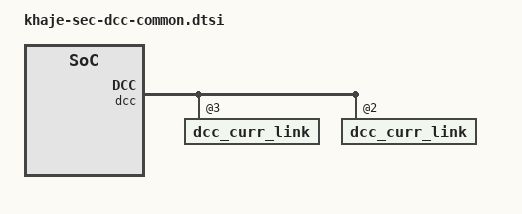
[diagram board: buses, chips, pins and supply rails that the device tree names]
// SPDX-License-Identifier: GPL-2.0
/*
 * COPYRIGHT(C) 2023 Samsung Electronics Co., Ltd. All Right Reserved.
 */

#include <dt-bindings/soc/qcom,dcc_v2.h>


/* config_bengal_dcc_bimc() */
#define config_bengal_dcc_bimc	\
	\
		/* BIMC_M_APP_MPORT */	\
		<DCC_READ 0x4488100 1 0>,	\
		<DCC_READ 0x4488400 2 0>,	\
		<DCC_READ 0x4488410 1 0>,	\
		<DCC_READ 0x4488420 2 0>,	\
		<DCC_READ 0x4488430 2 0>,	\
	\
		/* BIMC_M_GPU_MPORT */	\
		<DCC_READ 0x448c100 1 0>,	\
		<DCC_READ 0x448c400 2 0>,	\
		<DCC_READ 0x448c410 1 0>,	\
		<DCC_READ 0x448c420 2 0>,	\
		<DCC_READ 0x448c430 2 0>,	\
	\
		/* BIMC_M_MMSS_RT_MPORT */	\
		<DCC_READ 0x4490100 1 0>,	\
		<DCC_READ 0x4490400 2 0>,	\
		<DCC_READ 0x4490410 1 0>,	\
		<DCC_READ 0x4490420 2 0>,	\
		<DCC_READ 0x4490430 2 0>,	\
	\
		/* BIMC_M_MMSS_NRT_MPORT */	\
		<DCC_READ 0x4494100 1 0>,	\
		<DCC_READ 0x4494400 2 0>,	\
		<DCC_READ 0x4494410 1 0>,	\
		<DCC_READ 0x4494420 2 0>,	\
		<DCC_READ 0x4494430 2 0>,	\
	\
		/* BIMC_M_TCU_MPORT */	\
		<DCC_READ 0x449810c 1 0>,	\
		<DCC_READ 0x4498400 2 0>,	\
		<DCC_READ 0x4498410 1 0>,	\
		<DCC_READ 0x4498420 2 0>,	\
		<DCC_READ 0x4498430 2 0>,	\
	\
		/* BIMC_M_MDSP_MPORT */	\
		/* <DCC_READ 0x449c100 1 0>, */	\
		/* <DCC_READ 0x449c400 2 0>, */	\
		/* <DCC_READ 0x449c410 1 0>, */	\
		/* <DCC_READ 0x449c420 2 0>, */	\
		/* <DCC_READ 0x449c430 2 0>, */	\
	\
		/* BIMC_M_SYS_MPORT */	\
		<DCC_READ 0x44a0100 1 0>,	\
		<DCC_READ 0x44a0400 2 0>,	\
		<DCC_READ 0x44a0410 1 0>,	\
		<DCC_READ 0x44a0420 2 0>,	\
		<DCC_READ 0x44a0430 2 0>,	\
	\
		/* BIMC_S_DDR0 */	\
		<DCC_READ 0x44b0560 1 0>,	\
		<DCC_READ 0x44b05a0 1 0>,	\
		<DCC_READ 0x44b1800 1 0>,	\
		<DCC_READ 0x44b408c 1 0>,	\
		<DCC_READ 0x44b409c 1 0>,	\
		<DCC_READ 0x44b0520 1 0>,	\
		<DCC_READ 0x44b5070 2 0>,	\
	\
		/*  BIMC_S_SYS_SWAY */	\
		<DCC_READ 0x44bc220 1 0>,	\
		<DCC_READ 0x44bc400 7 0>,	\
		<DCC_READ 0x44bc420 9 0>,	\
		<DCC_READ 0x44bd800 1 0>,	\
		<DCC_READ 0x44c5800 1 0>,	\
		<DCC_READ 0x4480040 2 0>,	\
		<DCC_READ 0x4480810 2 0>,	\
		<DCC_READ 0x44b0a40 1 0>,	\
	\
		/* CH0_DDRCC */	\
		<DCC_READ 0x4506044 1 0>,	\
		<DCC_READ 0x45061dc 1 0>,	\
		<DCC_READ 0x45061ec 1 0>,	\
		<DCC_READ 0x4506028 2 0>,	\
		<DCC_READ 0x4506094 1 0>,	\
		<DCC_READ 0x4506608 1 0>,	\
	\
		/* CCC_MCCC_CH0 */	\
		<DCC_READ 0x447d02c 4 0>,	\
		<DCC_READ 0x447d040 1 0>,	\
	\
		/* CH0_CA0_DDRPHY */	\
		<DCC_READ 0x450002c 2 0>,	\
		<DCC_READ 0x4500094 1 0>,	\
		<DCC_READ 0x450009c 1 0>,	\
		<DCC_READ 0x45000c4 2 0>,	\
		<DCC_READ 0x45003dc 1 0>,	\
		<DCC_READ 0x45005d8 1 0>,	\
	\
		/* CH0_CA1_DDRPHY */	\
		<DCC_READ 0x450102c 2 0>,	\
		<DCC_READ 0x4501094 1 0>,	\
		<DCC_READ 0x450109c 1 0>,	\
		<DCC_READ 0x45010c4 2 0>,	\
		<DCC_READ 0x45013dc 1 0>,	\
		<DCC_READ 0x45015d8 1 0>,	\
	\
		/* CH0_DQ0_DDRPHY */	\
		<DCC_READ 0x450202c 2 0>,	\
		<DCC_READ 0x4502094 1 0>,	\
		<DCC_READ 0x450209c 1 0>,	\
		<DCC_READ 0x45020c4 2 0>,	\
		<DCC_READ 0x45023dc 1 0>,	\
		<DCC_READ 0x45025d8 1 0>,	\
	\
		/* CH0_DQ1_DDRPHY */	\
		<DCC_READ 0x450302c 2 0>,	\
		<DCC_READ 0x4503094 1 0>,	\
		<DCC_READ 0x450309c 1 0>,	\
		<DCC_READ 0x45030c4 2 0>,	\
		<DCC_READ 0x45033dc 1 0>,	\
		<DCC_READ 0x45035d8 1 0>,	\
	\
		/* CH0_DQ2_DDRPHY */	\
		<DCC_READ 0x450402c 2 0>,	\
		<DCC_READ 0x4504094 1 0>,	\
		<DCC_READ 0x450409c 1 0>,	\
		<DCC_READ 0x45040c8 2 0>,	\
		<DCC_READ 0x45043dc 1 0>,	\
		<DCC_READ 0x45045d8 1 0>,	\
	\
		/* CH0_DQ3_DDRPHY */	\
		<DCC_READ 0x450502c 2 0>,	\
		<DCC_READ 0x4505094 1 0>,	\
		<DCC_READ 0x450509c 1 0>,	\
		<DCC_READ 0x45050c4 2 0>,	\
		<DCC_READ 0x45053dc 1 0>,	\
		<DCC_READ 0x45055d8 1 0>

/* config_bengal_dcc_osm() */
#define config_bengal_dcc_osm	\
		<DCC_READ 0x0F522C14 1 0>,	\
		<DCC_READ 0x0F522C1C 1 0>,	\
		<DCC_READ 0x0F522C10 1 0>,	\
		<DCC_READ 0x0F524C10 1 0>,	\
		<DCC_READ 0x0F524C14 1 0>,	\
		<DCC_READ 0x0F524C18 1 0>,	\
		<DCC_READ 0x0F524C1C 1 0>,	\
		<DCC_READ 0x0F521920 1 0>,	\
		<DCC_READ 0x0F52102C 1 0>,	\
		<DCC_READ 0x0F521044 1 0>,	\
		<DCC_READ 0x0F521710 1 0>,	\
		<DCC_READ 0x0F52176C 1 0>,	\
		<DCC_READ 0x0F523920 1 0>,	\
		<DCC_READ 0x0F52302C 1 0>,	\
		<DCC_READ 0x0F523044 1 0>,	\
		<DCC_READ 0x0F523710 1 0>,	\
		<DCC_READ 0x0F52376C 1 0>,	\
		<DCC_READ 0x0F116000 1 0>,	\
		<DCC_READ 0x0F116004 1 0>,	\
		<DCC_READ 0x0F11602C 1 0>,	\
		<DCC_READ 0x0F016000 1 0>,	\
		<DCC_READ 0x0F016004 1 0>,	\
		<DCC_READ 0x0F01602C 1 0>,	\
		<DCC_READ 0x0F111250 1 0>,	\
		<DCC_READ 0x0F111254 1 0>,	\
		<DCC_READ 0x0F111258 1 0>,	\
		<DCC_READ 0x0F11125C 1 0>,	\
		<DCC_READ 0x0F111260 1 0>,	\
		<DCC_READ 0x0F188078 1 0>,	\
		<DCC_READ 0x0F188084 1 0>,	\
		<DCC_READ 0x0F198078 1 0>,	\
		<DCC_READ 0x0F198084 1 0>,	\
		<DCC_READ 0x0F1A8078 1 0>,	\
		<DCC_READ 0x0F1A8084 1 0>,	\
		<DCC_READ 0x0F1B8078 1 0>,	\
		<DCC_READ 0x0F1B8084 1 0>,	\
		<DCC_READ 0x0F521818 1 0>,	\
		<DCC_READ 0x0F52181C 1 0>,	\
		<DCC_READ 0x0F521828 1 0>,	\
		<DCC_READ 0x0F523818 1 0>,	\
		<DCC_READ 0x0F52381C 1 0>,	\
		<DCC_READ 0x0F523828 1 0>,	\
		<DCC_READ 0x0F522C18 1 0>,	\
		<DCC_READ 0x0F111310 1 0>,	\
		<DCC_READ 0x0F111314 1 0>,	\
		<DCC_READ 0x0F111318 1 0>,	\
		<DCC_READ 0x0F01125C 1 0>,	\
		<DCC_READ 0x0F011258 1 0>,	\
		<DCC_READ 0x0F011310 1 0>,	\
		<DCC_READ 0x0F011314 1 0>,	\
		<DCC_READ 0x0F011318 1 0>

/* config_bengal_dcc_gpu() */
#define config_bengal_dcc_gpu	\
	\
		/* GCC */	\
		<DCC_READ 0x141102C 1 0>,	\
		<DCC_READ 0x1436004 1 0>,	\
		<DCC_READ 0x1471154 1 0>,	\
		<DCC_READ 0x141050C 1 0>,	\
		<DCC_READ 0x143600C 1 0>,	\
		<DCC_READ 0x1436018 1 0>,	\
		<DCC_READ 0x1480220 1 0>,	\
		<DCC_READ 0x147C000 1 0>,	\
		<DCC_READ 0x147D000 1 0>,	\
		<DCC_READ 0x14800A0 1 0>,	\
		<DCC_READ 0x1480164 1 0>,	\
		<DCC_READ 0x14801E4 1 0>,	\
		<DCC_READ 0x1436048 1 0>,	\
		<DCC_READ 0x1436040 1 0>,	\
	\
		/* GPUCC */	\
		<DCC_READ 0x5991004 1 0>,	\
		<DCC_READ 0x599100c 1 0>,	\
		<DCC_READ 0x5991010 1 0>,	\
		<DCC_READ 0x5991014 1 0>,	\
		<DCC_READ 0x5991054 1 0>,	\
		<DCC_READ 0x5991060 1 0>,	\
		<DCC_READ 0x599106c 1 0>,	\
		<DCC_READ 0x5991070 1 0>,	\
		<DCC_READ 0x5991074 1 0>,	\
		<DCC_READ 0x5991078 1 0>,	\
		<DCC_READ 0x599107c 1 0>,	\
		<DCC_READ 0x599108c 1 0>,	\
		<DCC_READ 0x5991098 1 0>,	\
		<DCC_READ 0x599109c 1 0>,	\
		<DCC_READ 0x5991540 1 0>,	\
		<DCC_READ 0x5995000 1 0>,	\
		<DCC_READ 0x5995004 1 0>,	\
		<DCC_READ 0x599101C 1 0>,	\
		<DCC_READ 0x5991020 1 0>,	\
		<DCC_READ 0x5990000 1 0>,	\
		<DCC_READ 0x5990100 1 0>,	\
		<DCC_READ 0x5991508 1 0>,	\
		<DCC_READ 0x59910A4 1 0>,	\
		<DCC_READ 0x5991578 1 0>,	\
		<DCC_READ 0x5990010 1 0>,	\
		<DCC_READ 0x5990110 1 0>

/* config_bengal_dcc_gcc_mm() */
#define config_bengal_dcc_gcc_mm	\
		<DCC_READ 0x01480140 1 0>,	\
		<DCC_READ 0x01481140 1 0>,	\
		<DCC_READ 0x0148014C 1 0>,	\
		<DCC_READ 0x0148114C 1 0>,	\
		<DCC_READ 0x01477008 1 0>,	\
		<DCC_READ 0x01439014 1 0>,	\
		<DCC_READ 0x0143900C 1 0>,	\
		<DCC_READ 0x01439004 1 0>,	\
		<DCC_READ 0x01439000 1 0>,	\
		<DCC_READ 0x01439008 1 0>,	\
		<DCC_READ 0x01415010 1 0>,	\
		<DCC_READ 0x01416010 1 0>,	\
		<DCC_READ 0x0142A00C 1 0>

/* config_bengal_dcc_gcc() */
#define config_bengal_dcc_gcc	\
		<DCC_READ 0x1400000 1 0>,	\
		<DCC_READ 0x1400004 1 0>,	\
		<DCC_READ 0x1400008 1 0>,	\
		<DCC_READ 0x140000C 1 0>,	\
		<DCC_READ 0x1400010 1 0>,	\
		<DCC_READ 0x1400014 1 0>,	\
		<DCC_READ 0x1400018 1 0>,	\
		<DCC_READ 0x140001C 1 0>,	\
		<DCC_READ 0x1400020 1 0>,	\
		<DCC_READ 0x1400024 1 0>,	\
		<DCC_READ 0x1401000 1 0>,	\
		<DCC_READ 0x1401004 1 0>,	\
		<DCC_READ 0x1401008 1 0>,	\
		<DCC_READ 0x140100C 1 0>,	\
		<DCC_READ 0x1401010 1 0>,	\
		<DCC_READ 0x1401014 1 0>,	\
		<DCC_READ 0x1401018 1 0>,	\
		<DCC_READ 0x140101C 1 0>,	\
		<DCC_READ 0x1401020 1 0>,	\
		<DCC_READ 0x1401024 1 0>,	\
		<DCC_READ 0x1402000 1 0>,	\
		<DCC_READ 0x1402004 1 0>,	\
		<DCC_READ 0x1402008 1 0>,	\
		<DCC_READ 0x140200C 1 0>,	\
		<DCC_READ 0x1402010 1 0>,	\
		<DCC_READ 0x1402014 1 0>,	\
		<DCC_READ 0x1402018 1 0>,	\
		<DCC_READ 0x140201C 1 0>,	\
		<DCC_READ 0x1402020 1 0>,	\
		<DCC_READ 0x1402024 1 0>,	\
		<DCC_READ 0x1403000 1 0>,	\
		<DCC_READ 0x1403004 1 0>,	\
		<DCC_READ 0x1403008 1 0>,	\
		<DCC_READ 0x140300C 1 0>,	\
		<DCC_READ 0x1403010 1 0>,	\
		<DCC_READ 0x1403014 1 0>,	\
		<DCC_READ 0x1403018 1 0>,	\
		<DCC_READ 0x140301C 1 0>,	\
		<DCC_READ 0x1403020 1 0>,	\
		<DCC_READ 0x1403024 1 0>,	\
		<DCC_READ 0x1404000 1 0>,	\
		<DCC_READ 0x1404004 1 0>,	\
		<DCC_READ 0x1404008 1 0>,	\
		<DCC_READ 0x140400C 1 0>,	\
		<DCC_READ 0x1404010 1 0>,	\
		<DCC_READ 0x1404014 1 0>,	\
		<DCC_READ 0x1404018 1 0>,	\
		<DCC_READ 0x140401C 1 0>,	\
		<DCC_READ 0x1404020 1 0>,	\
		<DCC_READ 0x1404024 1 0>,	\
		<DCC_READ 0x1405000 1 0>,	\
		<DCC_READ 0x1405004 1 0>,	\
		<DCC_READ 0x1405008 1 0>,	\
		<DCC_READ 0x140500C 1 0>,	\
		<DCC_READ 0x1405010 1 0>,	\
		<DCC_READ 0x1405014 1 0>,	\
		<DCC_READ 0x1405018 1 0>,	\
		<DCC_READ 0x140501C 1 0>,	\
		<DCC_READ 0x1405020 1 0>,	\
		<DCC_READ 0x1405024 1 0>,	\
		<DCC_READ 0x1406000 1 0>,	\
		<DCC_READ 0x1406004 1 0>,	\
		<DCC_READ 0x1406008 1 0>,	\
		<DCC_READ 0x140600C 1 0>,	\
		<DCC_READ 0x1406010 1 0>,	\
		<DCC_READ 0x1406014 1 0>,	\
		<DCC_READ 0x1406018 1 0>,	\
		<DCC_READ 0x140601C 1 0>,	\
		<DCC_READ 0x1406020 1 0>,	\
		<DCC_READ 0x1406024 1 0>,	\
		<DCC_READ 0x1407000 1 0>,	\
		<DCC_READ 0x1407004 1 0>,	\
		<DCC_READ 0x1407008 1 0>,	\
		<DCC_READ 0x140700C 1 0>,	\
		<DCC_READ 0x1407010 1 0>,	\
		<DCC_READ 0x1407014 1 0>,	\
		<DCC_READ 0x1407018 1 0>,	\
		<DCC_READ 0x140701C 1 0>,	\
		<DCC_READ 0x1407020 1 0>,	\
		<DCC_READ 0x1407024 1 0>,	\
		<DCC_READ 0x1407028 1 0>,	\
		<DCC_READ 0x140702C 1 0>,	\
		<DCC_READ 0x1407030 1 0>,	\
		<DCC_READ 0x1407034 1 0>,	\
		<DCC_READ 0x1408000 1 0>,	\
		<DCC_READ 0x1408004 1 0>,	\
		<DCC_READ 0x1408008 1 0>,	\
		<DCC_READ 0x140800C 1 0>,	\
		<DCC_READ 0x1408010 1 0>,	\
		<DCC_READ 0x1408014 1 0>,	\
		<DCC_READ 0x1408018 1 0>,	\
		<DCC_READ 0x140801C 1 0>,	\
		<DCC_READ 0x1408020 1 0>,	\
		<DCC_READ 0x1408024 1 0>,	\
		<DCC_READ 0x1409000 1 0>,	\
		<DCC_READ 0x1409004 1 0>,	\
		<DCC_READ 0x1409008 1 0>,	\
		<DCC_READ 0x140900C 1 0>,	\
		<DCC_READ 0x1409010 1 0>,	\
		<DCC_READ 0x1409014 1 0>,	\
		<DCC_READ 0x1409018 1 0>,	\
		<DCC_READ 0x140901C 1 0>,	\
		<DCC_READ 0x1409020 1 0>,	\
		<DCC_READ 0x1409024 1 0>,	\
		<DCC_READ 0x141001C 1 0>,	\
		<DCC_READ 0x14103EC 1 0>,	\
		<DCC_READ 0x1414024 1 0>,	\
		<DCC_READ 0x1415004 1 0>,	\
		<DCC_READ 0x1415008 1 0>,	\
		<DCC_READ 0x141500C 1 0>,	\
		<DCC_READ 0x1415034 1 0>,	\
		<DCC_READ 0x1416004 1 0>,	\
		<DCC_READ 0x1416008 1 0>,	\
		<DCC_READ 0x141600C 1 0>,	\
		<DCC_READ 0x1416038 1 0>,	\
		<DCC_READ 0x141703C 1 0>,	\
		<DCC_READ 0x1417040 1 0>,	\
		<DCC_READ 0x141A004 1 0>,	\
		<DCC_READ 0x141A008 1 0>,	\
		<DCC_READ 0x141A00C 1 0>,	\
		<DCC_READ 0x141A01C 1 0>,	\
		<DCC_READ 0x141A020 1 0>,	\
		<DCC_READ 0x141A034 1 0>,	\
		<DCC_READ 0x141A038 1 0>,	\
		<DCC_READ 0x141A060 1 0>,	\
		<DCC_READ 0x141A064 1 0>,	\
		<DCC_READ 0x141E00C 1 0>,	\
		<DCC_READ 0x141E010 1 0>,	\
		<DCC_READ 0x141F02C 1 0>,	\
		<DCC_READ 0x141F148 1 0>,	\
		<DCC_READ 0x141F14C 1 0>,	\
		<DCC_READ 0x141F15C 1 0>,	\
		<DCC_READ 0x141F278 1 0>,	\
		<DCC_READ 0x141F27C 1 0>,	\
		<DCC_READ 0x141F28C 1 0>,	\
		<DCC_READ 0x141F3A8 1 0>,	\
		<DCC_READ 0x141F3AC 1 0>,	\
		<DCC_READ 0x141F3BC 1 0>,	\
		<DCC_READ 0x141F4D8 1 0>,	\
		<DCC_READ 0x141F4DC 1 0>,	\
		<DCC_READ 0x141F4EC 1 0>,	\
		<DCC_READ 0x141F608 1 0>,	\
		<DCC_READ 0x141F60C 1 0>,	\
		<DCC_READ 0x141F61C 1 0>,	\
		<DCC_READ 0x141F738 1 0>,	\
		<DCC_READ 0x141F73C 1 0>,	\
		<DCC_READ 0x141F74C 1 0>,	\
		<DCC_READ 0x1420010 1 0>,	\
		<DCC_READ 0x1420014 1 0>,	\
		<DCC_READ 0x1426018 1 0>,	\
		<DCC_READ 0x142601C 1 0>,	\
		<DCC_READ 0x1426030 1 0>,	\
		<DCC_READ 0x1426034 1 0>,	\
		<DCC_READ 0x1427024 1 0>,	\
		<DCC_READ 0x1428014 1 0>,	\
		<DCC_READ 0x1428018 1 0>,	\
		<DCC_READ 0x142802C 1 0>,	\
		<DCC_READ 0x1428030 1 0>,	\
		<DCC_READ 0x1429004 1 0>,	\
		<DCC_READ 0x1429008 1 0>,	\
		<DCC_READ 0x142900C 1 0>,	\
		<DCC_READ 0x1429040 1 0>,	\
		<DCC_READ 0x1429044 1 0>,	\
		<DCC_READ 0x142A000 1 0>,	\
		<DCC_READ 0x142A004 1 0>,	\
		<DCC_READ 0x142A008 1 0>,	\
		<DCC_READ 0x142A154 1 0>,	\
		<DCC_READ 0x142A158 1 0>,	\
		<DCC_READ 0x142B13C 1 0>,	\
		<DCC_READ 0x142B140 1 0>,	\
		<DCC_READ 0x142B158 1 0>,	\
		<DCC_READ 0x142B15C 1 0>,	\
		<DCC_READ 0x142E00C 1 0>,	\
		<DCC_READ 0x142E010 1 0>,	\
		<DCC_READ 0x142F00C 1 0>,	\
		<DCC_READ 0x142F010 1 0>,	\
		<DCC_READ 0x1432004 1 0>,	\
		<DCC_READ 0x1432008 1 0>,	\
		<DCC_READ 0x143200C 1 0>,	\
		<DCC_READ 0x1432034 1 0>,	\
		<DCC_READ 0x1432080 1 0>,	\
		<DCC_READ 0x1436024 1 0>,	\
		<DCC_READ 0x1436028 1 0>,	\
		<DCC_READ 0x1438010 1 0>,	\
		<DCC_READ 0x1438014 1 0>,	\
		<DCC_READ 0x1438028 1 0>,	\
		<DCC_READ 0x143802C 1 0>,	\
		<DCC_READ 0x1439148 1 0>,	\
		<DCC_READ 0x143914C 1 0>,	\
		<DCC_READ 0x143915C 1 0>,	\
		<DCC_READ 0x1439278 1 0>,	\
		<DCC_READ 0x143927C 1 0>,	\
		<DCC_READ 0x143928C 1 0>,	\
		<DCC_READ 0x14393A8 1 0>,	\
		<DCC_READ 0x14393AC 1 0>,	\
		<DCC_READ 0x14393BC 1 0>,	\
		<DCC_READ 0x14394D8 1 0>,	\
		<DCC_READ 0x14394DC 1 0>,	\
		<DCC_READ 0x14394EC 1 0>,	\
		<DCC_READ 0x1439608 1 0>,	\
		<DCC_READ 0x143960C 1 0>,	\
		<DCC_READ 0x143961C 1 0>,	\
		<DCC_READ 0x1439738 1 0>,	\
		<DCC_READ 0x143973C 1 0>,	\
		<DCC_READ 0x143974C 1 0>,	\
		<DCC_READ 0x143B000 1 0>,	\
		<DCC_READ 0x143B004 1 0>,	\
		<DCC_READ 0x143B008 1 0>,	\
		<DCC_READ 0x143B00C 1 0>,	\
		<DCC_READ 0x143B010 1 0>,	\
		<DCC_READ 0x143B014 1 0>,	\
		<DCC_READ 0x143B018 1 0>,	\
		<DCC_READ 0x143B01C 1 0>,	\
		<DCC_READ 0x143B020 1 0>,	\
		<DCC_READ 0x143B024 1 0>,	\
		<DCC_READ 0x143B028 1 0>,	\
		<DCC_READ 0x143D01C 1 0>,	\
		<DCC_READ 0x143D020 1 0>,	\
		<DCC_READ 0x143E000 1 0>,	\
		<DCC_READ 0x143E004 1 0>,	\
		<DCC_READ 0x143E008 1 0>,	\
		<DCC_READ 0x143E00C 1 0>,	\
		<DCC_READ 0x143E010 1 0>,	\
		<DCC_READ 0x143E014 1 0>,	\
		<DCC_READ 0x143E018 1 0>,	\
		<DCC_READ 0x143E01C 1 0>,	\
		<DCC_READ 0x143E020 1 0>,	\
		<DCC_READ 0x143E024 1 0>,	\
		<DCC_READ 0x143E028 1 0>,	\
		<DCC_READ 0x143E060 1 0>,	\
		<DCC_READ 0x143F000 1 0>,	\
		<DCC_READ 0x143F004 1 0>,	\
		<DCC_READ 0x143F008 1 0>,	\
		<DCC_READ 0x143F00C 1 0>,	\
		<DCC_READ 0x143F010 1 0>,	\
		<DCC_READ 0x143F014 1 0>,	\
		<DCC_READ 0x143F018 1 0>,	\
		<DCC_READ 0x143F01C 1 0>,	\
		<DCC_READ 0x143F020 1 0>,	\
		<DCC_READ 0x143F024 1 0>,	\
		<DCC_READ 0x143F028 1 0>,	\
		<DCC_READ 0x1442018 1 0>,	\
		<DCC_READ 0x144201C 1 0>,	\
		<DCC_READ 0x1442030 1 0>,	\
		<DCC_READ 0x1442034 1 0>,	\
		<DCC_READ 0x1445004 1 0>,	\
		<DCC_READ 0x1445008 1 0>,	\
		<DCC_READ 0x144500C 1 0>,	\
		<DCC_READ 0x1445020 1 0>,	\
		<DCC_READ 0x1445024 1 0>,	\
		<DCC_READ 0x1445048 1 0>,	\
		<DCC_READ 0x144504C 1 0>,	\
		<DCC_READ 0x1445060 1 0>,	\
		<DCC_READ 0x1445064 1 0>,	\
		<DCC_READ 0x144507C 1 0>,	\
		<DCC_READ 0x1445080 1 0>,	\
		<DCC_READ 0x1446004 1 0>,	\
		<DCC_READ 0x1446008 1 0>,	\
		<DCC_READ 0x1446024 1 0>,	\
		<DCC_READ 0x1446150 1 0>,	\
		<DCC_READ 0x1448024 1 0>,	\
		<DCC_READ 0x144D004 1 0>,	\
		<DCC_READ 0x144D008 1 0>,	\
		<DCC_READ 0x144E004 1 0>,	\
		<DCC_READ 0x144E008 1 0>,	\
		<DCC_READ 0x144F004 1 0>,	\
		<DCC_READ 0x144F008 1 0>,	\
		<DCC_READ 0x1450000 1 0>,	\
		<DCC_READ 0x1450004 1 0>,	\
		<DCC_READ 0x145001C 1 0>,	\
		<DCC_READ 0x1450020 1 0>,	\
		<DCC_READ 0x1451000 1 0>,	\
		<DCC_READ 0x1451004 1 0>,	\
		<DCC_READ 0x145101C 1 0>,	\
		<DCC_READ 0x1451020 1 0>,	\
		<DCC_READ 0x1451038 1 0>,	\
		<DCC_READ 0x145103C 1 0>,	\
		<DCC_READ 0x1451054 1 0>,	\
		<DCC_READ 0x1451058 1 0>,	\
		<DCC_READ 0x1452004 1 0>,	\
		<DCC_READ 0x1452008 1 0>,	\
		<DCC_READ 0x1452028 1 0>,	\
		<DCC_READ 0x145202C 1 0>,	\
		<DCC_READ 0x1453004 1 0>,	\
		<DCC_READ 0x1453008 1 0>,	\
		<DCC_READ 0x1453024 1 0>,	\
		<DCC_READ 0x1453028 1 0>,	\
		<DCC_READ 0x1453044 1 0>,	\
		<DCC_READ 0x1453048 1 0>,	\
		<DCC_READ 0x1454004 1 0>,	\
		<DCC_READ 0x1454008 1 0>,	\
		<DCC_READ 0x145400C 1 0>,	\
		<DCC_READ 0x1454010 1 0>,	\
		<DCC_READ 0x1454014 1 0>,	\
		<DCC_READ 0x145403C 1 0>,	\
		<DCC_READ 0x1454040 1 0>,	\
		<DCC_READ 0x1454044 1 0>,	\
		<DCC_READ 0x1454048 1 0>,	\
		<DCC_READ 0x145404C 1 0>,	\
		<DCC_READ 0x1455000 1 0>,	\
		<DCC_READ 0x1455004 1 0>,	\
		<DCC_READ 0x1455030 1 0>,	\
		<DCC_READ 0x1455034 1 0>,	\
		<DCC_READ 0x145506C 1 0>,	\
		<DCC_READ 0x1455070 1 0>,	\
		<DCC_READ 0x14550A4 1 0>,	\
		<DCC_READ 0x14550A8 1 0>,	\
		<DCC_READ 0x14550E0 1 0>,	\
		<DCC_READ 0x14550E4 1 0>,	\
		<DCC_READ 0x145607C 1 0>,	\
		<DCC_READ 0x1456080 1 0>,	\
		<DCC_READ 0x1456084 1 0>,	\
		<DCC_READ 0x1456088 1 0>,	\
		<DCC_READ 0x145608C 1 0>,	\
		<DCC_READ 0x14560BC 1 0>,	\
		<DCC_READ 0x14560C0 1 0>,	\
		<DCC_READ 0x14560C4 1 0>,	\
		<DCC_READ 0x14560C8 1 0>,	\
		<DCC_READ 0x14560CC 1 0>,	\
		<DCC_READ 0x1457000 1 0>,	\
		<DCC_READ 0x1457004 1 0>,	\
		<DCC_READ 0x1457008 1 0>,	\
		<DCC_READ 0x145700C 1 0>,	\
		<DCC_READ 0x1457010 1 0>,	\
		<DCC_READ 0x145A000 1 0>,	\
		<DCC_READ 0x145A004 1 0>,	\
		<DCC_READ 0x145A008 1 0>,	\
		<DCC_READ 0x145A00C 1 0>,	\
		<DCC_READ 0x145A010 1 0>,	\
		<DCC_READ 0x145B000 1 0>,	\
		<DCC_READ 0x145B004 1 0>,	\
		<DCC_READ 0x145B00C 1 0>,	\
		<DCC_READ 0x1463020 1 0>,	\
		<DCC_READ 0x1469000 1 0>,	\
		<DCC_READ 0x1469004 1 0>,	\
		<DCC_READ 0x1469008 1 0>,	\
		<DCC_READ 0x146900C 1 0>,	\
		<DCC_READ 0x1469010 1 0>,	\
		<DCC_READ 0x146B000 1 0>,	\
		<DCC_READ 0x146B004 1 0>,	\
		<DCC_READ 0x146B008 1 0>,	\
		<DCC_READ 0x146B00C 1 0>,	\
		<DCC_READ 0x146B010 1 0>,	\
		<DCC_READ 0x146B014 1 0>,	\
		<DCC_READ 0x146B018 1 0>,	\
		<DCC_READ 0x146B01C 1 0>,	\
		<DCC_READ 0x146B020 1 0>,	\
		<DCC_READ 0x146C000 1 0>,	\
		<DCC_READ 0x146C004 1 0>,	\
		<DCC_READ 0x146C00C 1 0>,	\
		<DCC_READ 0x1475000 1 0>,	\
		<DCC_READ 0x1475004 1 0>,	\
		<DCC_READ 0x147500C 1 0>,	\
		<DCC_READ 0x1477000 1 0>,	\
		<DCC_READ 0x1477004 1 0>,	\
		<DCC_READ 0x147700C 1 0>,	\
		<DCC_READ 0x1478030 1 0>,	\
		<DCC_READ 0x1479000 1 0>,	\
		<DCC_READ 0x1479004 1 0>,	\
		<DCC_READ 0x147900C 1 0>,	\
		<DCC_READ 0x147A000 1 0>,	\
		<DCC_READ 0x147A004 1 0>,	\
		<DCC_READ 0x147A00C 1 0>,	\
		<DCC_READ 0x147B000 1 0>,	\
		<DCC_READ 0x147B004 1 0>,	\
		<DCC_READ 0x147B00C 1 0>,	\
		<DCC_READ 0x1480018 1 0>,	\
		<DCC_READ 0x1480028 1 0>,	\
		<DCC_READ 0x148005C 1 0>,	\
		<DCC_READ 0x1480144 1 0>,	\
		<DCC_READ 0x1480154 1 0>,	\
		<DCC_READ 0x14801B8 1 0>,	\
		<DCC_READ 0x14801C0 1 0>,	\
		<DCC_READ 0x14801C8 1 0>,	\
		<DCC_READ 0x14801D0 1 0>,	\
		<DCC_READ 0x1480250 1 0>,	\
		<DCC_READ 0x1480254 1 0>,	\
		<DCC_READ 0x1480258 1 0>,	\
		<DCC_READ 0x1480270 1 0>,	\
		<DCC_READ 0x1481144 1 0>,	\
		<DCC_READ 0x148B004 1 0>,	\
		<DCC_READ 0x1490004 1 0>,	\
		<DCC_READ 0x1490008 1 0>,	\
		<DCC_READ 0x1490024 1 0>,	\
		<DCC_READ 0x1490028 1 0>,	\
		<DCC_READ 0x149002C 1 0>,	\
		<DCC_READ 0x1490030 1 0>,	\
		<DCC_READ 0x1490034 1 0>,	\
		<DCC_READ 0x1495000 1 0>,	\
		<DCC_READ 0x1495004 1 0>,	\
		<DCC_READ 0x149500C 1 0>,	\
		<DCC_READ 0x14B5000 1 0>,	\
		<DCC_READ 0x14C4000 1 0>,	\
		<DCC_READ 0x14C5000 1 0>,	\
		<DCC_READ 0x14C6000 1 0>,	\
		<DCC_READ 0x14C7000 1 0>,	\
		<DCC_READ 0x440C000 1 0>,	\
		<DCC_READ 0x440C004 1 0>,	\
		<DCC_READ 0x440C008 1 0>,	\
		<DCC_READ 0x440C040 1 0>,	\
		<DCC_READ 0x440C044 1 0>,	\
		<DCC_READ 0x440C048 1 0>,	\
		<DCC_READ 0x440C04C 1 0>,	\
		<DCC_READ 0x440C050 1 0>,	\
		<DCC_READ 0x440C054 1 0>,	\
		<DCC_READ 0x440C058 1 0>,	\
		<DCC_READ 0x440C05C 1 0>,	\
		<DCC_READ 0x440C060 1 0>,	\
		<DCC_READ 0x440C068 1 0>,	\
		<DCC_READ 0x440C06C 1 0>,	\
		<DCC_READ 0x440E050 1 0>,	\
		<DCC_READ 0x440E054 1 0>,	\
		<DCC_READ 0x440E0A0 1 0>,	\
		<DCC_READ 0x440E0A4 1 0>,	\
		<DCC_READ 0x440F010 1 0>

/* config_bengal_dcc_lpm() */
#define config_bengal_dcc_lpm	\
	\
		/* APCS_ALIAS0_SAW4 */	\
		<DCC_READ 0xf189000 1 0>,	\
		<DCC_READ 0xf18900c 1 0>,	\
		<DCC_READ 0xf189c0c 1 0>,	\
		<DCC_READ 0xf189c10 1 0>,	\
		<DCC_READ 0xf189c20 1 0>,	\
	\
		/* APCS_ALIAS1_SAW4 */	\
		<DCC_READ 0xf199000 1 0>,	\
		<DCC_READ 0xf19900c 1 0>,	\
		<DCC_READ 0xf199c0c 1 0>,	\
		<DCC_READ 0xf199c10 1 0>,	\
		<DCC_READ 0xf199c20 1 0>,	\
	\
		/* APCS_ALIAS2_SAW4 */	\
		<DCC_READ 0xf1a9000 1 0>,	\
		<DCC_READ 0xf1a900c 1 0>,	\
		<DCC_READ 0xf1a9c0c 1 0>,	\
		<DCC_READ 0xf1a9c10 1 0>,	\
		<DCC_READ 0xf1a9c20 1 0>,	\
	\
		/* APCS_ALIAS3_SAW4 */	\
		<DCC_READ 0xf1b9000 1 0>,	\
		<DCC_READ 0xf1b900c 1 0>,	\
		<DCC_READ 0xf1b9c0c 1 0>,	\
		<DCC_READ 0xf1b9c10 1 0>,	\
		<DCC_READ 0xf1b9c18 1 0>,	\
	\
		/* APCS_ALIAS4_SAW4 */	\
		<DCC_READ 0xf089000 1 0>,	\
		<DCC_READ 0xf08900c 1 0>,	\
		<DCC_READ 0xf089c0c 1 0>,	\
		<DCC_READ 0xf089c10 1 0>,	\
		<DCC_READ 0xf089c20 1 0>,	\
	\
		/* APCS_ALIAS5_SAW4 */	\
		<DCC_READ 0xf099000 1 0>,	\
		<DCC_READ 0xf09900c 1 0>,	\
		<DCC_READ 0xf099c0c 1 0>,	\
		<DCC_READ 0xf099c10 1 0>,	\
		<DCC_READ 0xf099c20 1 0>,	\
	\
		/* APCS_ALIAS6_SAW4 */	\
		<DCC_READ 0xf0a9000 1 0>,	\
		<DCC_READ 0xf0a900c 1 0>,	\
		<DCC_READ 0xf0a9c0c 1 0>,	\
		<DCC_READ 0xf0a9c10 1 0>,	\
		<DCC_READ 0xf0a9c20 1 0>,	\
	\
		/* APCS_ALIAS7_SAW4 */	\
		<DCC_READ 0xf0b9000 1 0>,	\
		<DCC_READ 0xf0b900c 1 0>,	\
		<DCC_READ 0xf0b9c0c 1 0>,	\
		<DCC_READ 0xf0b9c10 1 0>,	\
		<DCC_READ 0xf0b9c20 1 0>,	\
	\
		/* APCLUS0_L2_SAW4 */	\
		<DCC_READ 0xf112000 1 0>,	\
		<DCC_READ 0xf11200c 1 0>,	\
		<DCC_READ 0xf112c0c 1 0>,	\
		<DCC_READ 0xf112c10 1 0>,	\
		<DCC_READ 0xf112c20 1 0>,	\
	\
		/* APCLUS1_L2_SAW4 */	\
		<DCC_READ 0xf012000 1 0>,	\
		<DCC_READ 0xf01200c 1 0>,	\
		<DCC_READ 0xf012c0c 1 0>,	\
		<DCC_READ 0xf012c10 1 0>,	\
		<DCC_READ 0xf012c20 1 0>,	\
	\
		/* CCI_SAW4 */	\
		<DCC_READ 0xf1d2000 1 0>,	\
		<DCC_READ 0xf1d200c 1 0>,	\
		<DCC_READ 0xf1d2c0c 1 0>,	\
		<DCC_READ 0xf1d2c10 1 0>,	\
		<DCC_READ 0xf1d2c20 1 0>,	\
	\
		/* APCS_ALIAS1_L2 */	\
		<DCC_READ 0xf011014 1 0>,	\
		<DCC_READ 0xf011018 1 0>,	\
		<DCC_READ 0xf011218 1 0>,	\
		<DCC_READ 0xf011234 1 0>,	\
		<DCC_READ 0xf011220 1 0>,	\
		<DCC_READ 0xf011264 1 0>,	\
		<DCC_READ 0xf011290 1 0>,	\
	\
		/* APCS_ALIAS0_L2 */	\
		<DCC_READ 0xf111014 1 0>,	\
		<DCC_READ 0xf111018 1 0>,	\
		<DCC_READ 0xf111218 1 0>,	\
		<DCC_READ 0xf111234 1 0>,	\
		<DCC_READ 0xf111264 1 0>,	\
		<DCC_READ 0xf111290 1 0>,	\
	\
		/* Curr Frequency */	\
		<DCC_READ 0x0F521700 1 0>,	\
		<DCC_READ 0x0F523700 1 0>,	\
	\
		/* Cluster voltage */	\
		<DCC_READ 0x0F112C18 1 0>,	\
		<DCC_READ 0x0F012C18 1 0>,	\
	\
		/* CPRh info */	\
		<DCC_READ 0x0F513A84 1 0>,	\
		<DCC_READ 0x0F513A88 1 0>,	\
	\
		/* PIMEM */	\
		<DCC_READ 0x01B60110 1 0>

/* config_bengal_dcc_noc() */
#define config_bengal_dcc_noc	\
		<DCC_READ 0x1900010 1 0>,	\
		<DCC_READ 0x1900020 1 0>,	\
		<DCC_READ 0x1900024 1 0>,	\
		<DCC_READ 0x1900028 1 0>,	\
		<DCC_READ 0x190002C 1 0>,	\
		<DCC_READ 0x1900030 1 0>,	\
		<DCC_READ 0x1900034 1 0>,	\
		<DCC_READ 0x1900038 1 0>,	\
		<DCC_READ 0x190003C 1 0>,	\
		<DCC_READ 0x1900300 1 0>,	\
		<DCC_READ 0x1900304 1 0>,	\
		<DCC_READ 0x1900308 1 0>,	\
		<DCC_READ 0x190030C 1 0>,	\
		<DCC_READ 0x1900310 1 0>,	\
		<DCC_READ 0x1900314 1 0>,	\
		<DCC_READ 0x1900900 1 0>,	\
		<DCC_READ 0x1900904 1 0>,	\
		<DCC_READ 0x1900B00 1 0>,	\
		<DCC_READ 0x1900D00 1 0>,	\
		<DCC_READ 0x1909100 1 0>,	\
		<DCC_READ 0x1909104 1 0>,	\
		<DCC_READ 0x1480140 1 0>,	\
		<DCC_READ 0x1481140 1 0>,	\
		<DCC_READ 0x1415008 1 0>,	\
		<DCC_READ 0x1416008 1 0>,	\
		<DCC_READ 0x44B0120 1 0>,	\
		<DCC_READ 0x44B0124 1 0>,	\
		<DCC_READ 0x44B0128 1 0>,	\
		<DCC_READ 0x44B012C 1 0>,	\
		<DCC_READ 0x44B0130 1 0>,	\
		<DCC_READ 0x44B0100 1 0>,	\
		<DCC_READ 0x44B0020 1 0>,	\
		<DCC_READ 0x44C4000 1 0>,	\
		<DCC_READ 0x44C4020 1 0>,	\
		<DCC_READ 0x44C4030 1 0>,	\
		<DCC_READ 0x44C4100 1 0>,	\
		<DCC_READ 0x44C410C 1 0>,	\
		<DCC_READ 0x44C4400 1 0>,	\
		<DCC_READ 0x44C4410 1 0>,	\
		<DCC_READ 0x44C4420 1 0>,	\
		<DCC_READ 0x1900240 1 0>,	\
		<DCC_READ 0x1900244 1 0>,	\
		<DCC_READ 0x1900248 1 0>,	\
		<DCC_READ 0x190024C 1 0>,	\
		<DCC_READ 0x1900250 1 0>,	\
		<DCC_READ 0x1900258 1 0>,	\
		<DCC_READ 0x1411004 1 0>,	\
		<DCC_READ 0x1411028 1 0>,	\
		/* <DCC_READ 0x141102C 1 0>, */	\
		<DCC_READ 0x1458004 1 0>,	\
		<DCC_READ 0x1880108 1 0>,	\
		<DCC_READ 0x1880110 1 0>,	\
		<DCC_READ 0x1880120 1 0>,	\
		<DCC_READ 0x1880124 1 0>,	\
		<DCC_READ 0x1880128 1 0>,	\
		<DCC_READ 0x188012C 1 0>,	\
		<DCC_READ 0x1880130 1 0>,	\
		<DCC_READ 0x1880134 1 0>,	\
		<DCC_READ 0x1880138 1 0>,	\
		<DCC_READ 0x188013C 1 0>,	\
		<DCC_READ 0x1880300 1 0>,	\
		<DCC_READ 0x1880304 1 0>,	\
		<DCC_READ 0x1880308 1 0>,	\
		<DCC_READ 0x188030C 1 0>,	\
		<DCC_READ 0x1880310 1 0>,	\
		<DCC_READ 0x1880314 1 0>,	\
		<DCC_READ 0x1880318 1 0>,	\
		<DCC_READ 0x188031C 1 0>,	\
		/* <DCC_READ 0x1880500 1 0>, */	\
		<DCC_READ 0x1880700 1 0>,	\
		<DCC_READ 0x1880704 1 0>,	\
		<DCC_READ 0x1880708 1 0>,	\
		<DCC_READ 0x188070C 1 0>,	\
		<DCC_READ 0x1880710 1 0>,	\
		<DCC_READ 0x1880714 1 0>,	\
		<DCC_READ 0x1880718 1 0>,	\
		<DCC_READ 0x188071C 1 0>,	\
		/* <DCC_READ 0x1880B00 1 0>, */	\
		/* <DCC_READ 0x1880B04 1 0>, */	\
		/* <DCC_READ 0x1880D00 1 0>, */	\
		<DCC_READ 0x1881100 1 0>,	\
		<DCC_READ 0x1880240 1 0>,	\
		<DCC_READ 0x1880248 1 0>

/* config_bengal_dcc_qdsp() */
#define config_bengal_dcc_qdsp	\
		<DCC_READ 0xA754520 1 0>,	\
		<DCC_READ 0xA751020 1 0>,	\
		<DCC_READ 0xA751024 1 0>,	\
		<DCC_READ 0xA751030 1 0>,	\
		<DCC_READ 0xA751200 1 0>,	\
		<DCC_READ 0xA751214 1 0>,	\
		<DCC_READ 0xA751228 1 0>,	\
		<DCC_READ 0xA75123C 1 0>,	\
		<DCC_READ 0xA751250 1 0>,	\
		<DCC_READ 0xA751204 1 0>,	\
		<DCC_READ 0xA751218 1 0>,	\
		<DCC_READ 0xA75122C 1 0>,	\
		<DCC_READ 0xA751240 1 0>,	\
		<DCC_READ 0xA751254 1 0>,	\
		<DCC_READ 0xA751208 1 0>,	\
		<DCC_READ 0xA75121C 1 0>,	\
		<DCC_READ 0xA751230 1 0>,	\
		<DCC_READ 0xA751244 1 0>,	\
		<DCC_READ 0xA751258 1 0>,	\
		<DCC_READ 0xA754510 1 0>,	\
		<DCC_READ 0xA754514 1 0>,	\
		<DCC_READ 0xA750010 1 0>,	\
		<DCC_READ 0xA750014 1 0>,	\
		<DCC_READ 0xA750900 1 0>,	\
		<DCC_READ 0xA750904 1 0>,	\
		<DCC_READ 0x0A402028 1 0>,	\
		<DCC_READ 0x0A900010 1 0>,	\
		<DCC_READ 0x0A900014 1 0>,	\
		<DCC_READ 0x0A900018 1 0>,	\
		<DCC_READ 0x0A900030 1 0>,	\
		<DCC_READ 0x0A900038 1 0>,	\
		<DCC_READ 0x0A900040 1 0>,	\
		<DCC_READ 0x0A900048 1 0>,	\
		<DCC_READ 0x0A9000D0 1 0>,	\
		<DCC_READ 0x0A900210 1 0>,	\
		<DCC_READ 0x0A900230 1 0>,	\
		<DCC_READ 0x0A900250 1 0>,	\
		<DCC_READ 0x0A900270 1 0>,	\
		<DCC_READ 0x0A900290 1 0>,	\
		<DCC_READ 0x0A9002B0 1 0>,	\
		<DCC_READ 0x0A900208 1 0>,	\
		<DCC_READ 0x0A900228 1 0>,	\
		<DCC_READ 0x0A900248 1 0>,	\
		<DCC_READ 0x0A900268 1 0>,	\
		<DCC_READ 0x0A900288 1 0>,	\
		<DCC_READ 0x0A9002A8 1 0>,	\
		<DCC_READ 0x0A90020C 1 0>,	\
		<DCC_READ 0x0A90022C 1 0>,	\
		<DCC_READ 0x0A90024C 1 0>,	\
		<DCC_READ 0x0A90026C 1 0>,	\
		<DCC_READ 0x0A90028C 1 0>,	\
		<DCC_READ 0x0A9002AC 1 0>,	\
		<DCC_READ 0x0A900404 1 0>,	\
		<DCC_READ 0x0A900408 1 0>,	\
		<DCC_READ 0x0A900400 1 0>,	\
		<DCC_READ 0x0A900D04 1 0>,	\
		<DCC_READ 0x0A4B0010 1 0>,	\
		<DCC_READ 0x0A4B0014 1 0>,	\
		<DCC_READ 0x0A4B0018 1 0>,	\
		<DCC_READ 0x0A4B0210 1 0>,	\
		<DCC_READ 0x0A4B0230 1 0>,	\
		<DCC_READ 0x0A4B0250 1 0>,	\
		<DCC_READ 0x0A4B0270 1 0>,	\
		<DCC_READ 0x0A4B0290 1 0>,	\
		<DCC_READ 0x0A4B02B0 1 0>,	\
		<DCC_READ 0x0A4B0208 1 0>,	\
		<DCC_READ 0x0A4B0228 1 0>,	\
		<DCC_READ 0x0A4B0248 1 0>,	\
		<DCC_READ 0x0A4B0268 1 0>,	\
		<DCC_READ 0x0A4B0288 1 0>,	\
		<DCC_READ 0x0A4B02A8 1 0>,	\
		<DCC_READ 0x0A4B020C 1 0>,	\
		<DCC_READ 0x0A4B022C 1 0>,	\
		<DCC_READ 0x0A4B024C 1 0>,	\
		<DCC_READ 0x0A4B026C 1 0>,	\
		<DCC_READ 0x0A4B028C 1 0>,	\
		<DCC_READ 0x0A4B02AC 1 0>,	\
		<DCC_READ 0x0A4B0400 1 0>,	\
		<DCC_READ 0x0A4B0404 1 0>,	\
		<DCC_READ 0x0A4B0408 1 0>

/* config_bengal_dcc_misc() */
#define config_bengal_dcc_misc	\
		<DCC_READ 0xF017000 1 0>,	\
		<DCC_READ 0xF01700C 1 0>,	\
		<DCC_READ 0xF017010 1 0>,	\
		<DCC_READ 0xF017014 1 0>,	\
		<DCC_READ 0xF017018 1 0>,	\
		<DCC_READ 0xF017020 1 0>,	\
		<DCC_READ 0x1414008 1 0>,	\
		<DCC_READ 0x1414004 1 0>,	\
		<DCC_READ 0x5991554 1 0>,	\
		<DCC_READ 0x5991544 1 0>,	\
		<DCC_READ 0x599155C 1 0>,	\
	\
		/* MPM_SSCAON_STATUS */	\
		<DCC_READ 0x440B00C 1 0>,	\
		<DCC_READ 0x440B014 1 0>

/* config_modem_rscc() */
#define config_modem_rscc	\
		<DCC_READ 0x06130010 1 0>,	\
		<DCC_READ 0x06130014 1 0>,	\
		<DCC_READ 0x06130018 1 0>,	\
		<DCC_READ 0x06130210 1 0>,	\
		<DCC_READ 0x06130230 1 0>,	\
		<DCC_READ 0x06130250 1 0>,	\
		<DCC_READ 0x06130270 1 0>,	\
		<DCC_READ 0x06130290 1 0>,	\
		<DCC_READ 0x061302B0 1 0>,	\
		<DCC_READ 0x06130208 1 0>,	\
		<DCC_READ 0x06130228 1 0>,	\
		<DCC_READ 0x06130248 1 0>,	\
		<DCC_READ 0x06130268 1 0>,	\
		<DCC_READ 0x06130288 1 0>,	\
		<DCC_READ 0x061302A8 1 0>,	\
		<DCC_READ 0x0613020C 1 0>,	\
		<DCC_READ 0x0613022C 1 0>,	\
		<DCC_READ 0x0613024C 1 0>,	\
		<DCC_READ 0x0613026C 1 0>,	\
		<DCC_READ 0x0613028C 1 0>,	\
		<DCC_READ 0x061302AC 1 0>,	\
		<DCC_READ 0x06130400 1 0>,	\
		<DCC_READ 0x06130404 1 0>,	\
		<DCC_READ 0x06130408 1 0>,	\
		<DCC_READ 0x6082028 1 0>,	\
		<DCC_READ 0x0143300C 1 0>

/* config_cdsp_rscc() */
#define config_cdsp_rscc	\
		<DCC_READ 0x0B3B0010 1 0>,	\
		<DCC_READ 0x0B3B0014 1 0>,	\
		<DCC_READ 0x0B3B0018 1 0>,	\
		<DCC_READ 0x0B3B0210 1 0>,	\
		<DCC_READ 0x0B3B0230 1 0>,	\
		<DCC_READ 0x0B3B0250 1 0>,	\
		<DCC_READ 0x0B3B0270 1 0>,	\
		<DCC_READ 0x0B3B0290 1 0>,	\
		<DCC_READ 0x0B3B02B0 1 0>,	\
		<DCC_READ 0x0B3B0208 1 0>,	\
		<DCC_READ 0x0B3B0228 1 0>,	\
		<DCC_READ 0x0B3B0248 1 0>,	\
		<DCC_READ 0x0B3B0268 1 0>,	\
		<DCC_READ 0x0B3B0288 1 0>,	\
		<DCC_READ 0x0B3B02A8 1 0>,	\
		<DCC_READ 0x0B3B020C 1 0>,	\
		<DCC_READ 0x0B3B022C 1 0>,	\
		<DCC_READ 0x0B3B024C 1 0>,	\
		<DCC_READ 0x0B3B026C 1 0>,	\
		<DCC_READ 0x0B3B028C 1 0>,	\
		<DCC_READ 0x0B3B02AC 1 0>,	\
		<DCC_READ 0x0B3B0400 1 0>,	\
		<DCC_READ 0x0B3B0404 1 0>,	\
		<DCC_READ 0x0B3B0408 1 0>,	\
		<DCC_READ 0x0B302028 1 0>,	\
		<DCC_READ 0x0B300044 1 0>,	\
		<DCC_READ 0x0B300304 1 0>

/* config_acp_status() */
#define config_acp_status	\
		<DCC_WRITE 0x9870010 0x14000 0>,	\
		<DCC_READ 0xF011600 1 0>,	\
		<DCC_READ 0xF011604 1 0>,	\
		<DCC_READ 0xF011608 1 0>,	\
		<DCC_READ 0xF01160C 1 0>,	\
		<DCC_READ 0xF011610 1 0>,	\
		<DCC_READ 0xF011614 1 0>,	\
		<DCC_READ 0xF011618 1 0>,	\
		<DCC_READ 0xF01161C 1 0>,	\
		<DCC_READ 0xF011620 1 0>,	\
		<DCC_READ 0xF011624 1 0>,	\
		<DCC_READ 0xF011628 1 0>,	\
		<DCC_READ 0xF01162C 1 0>,	\
		<DCC_READ 0xF011630 1 0>,	\
		<DCC_READ 0xF011634 1 0>,	\
		<DCC_READ 0xF011638 1 0>,	\
		<DCC_READ 0xF01163C 1 0>,	\
		<DCC_READ 0xF011640 1 0>,	\
		<DCC_READ 0xF011644 1 0>,	\
		<DCC_READ 0xF011648 1 0>,	\
		<DCC_READ 0xF01164C 1 0>,	\
		<DCC_READ 0xF011650 1 0>,	\
		<DCC_READ 0xF011654 1 0>,	\
		<DCC_READ 0xF011658 1 0>,	\
		<DCC_READ 0xF01165C 1 0>,	\
		<DCC_READ 0xF011660 1 0>,	\
		<DCC_READ 0xF011664 1 0>,	\
		<DCC_READ 0xF111600 1 0>,	\
		<DCC_READ 0xF111604 1 0>,	\
		<DCC_READ 0xF111608 1 0>,	\
		<DCC_READ 0xF11160C 1 0>,	\
		<DCC_READ 0xF111610 1 0>,	\
		<DCC_READ 0xF111614 1 0>,	\
		<DCC_READ 0xF111618 1 0>,	\
		<DCC_READ 0xF11161C 1 0>,	\
		<DCC_READ 0xF111620 1 0>,	\
		<DCC_READ 0xF111624 1 0>,	\
		<DCC_READ 0xF111628 1 0>,	\
		<DCC_READ 0xF11162C 1 0>,	\
		<DCC_READ 0xF111630 1 0>,	\
		<DCC_READ 0xF111634 1 0>,	\
		<DCC_READ 0xF111638 1 0>,	\
		<DCC_READ 0xF11163C 1 0>,	\
		<DCC_READ 0xF111640 1 0>,	\
		<DCC_READ 0xF111644 1 0>,	\
		<DCC_READ 0xF111648 1 0>,	\
		<DCC_READ 0xF11164C 1 0>,	\
		<DCC_READ 0xF111650 1 0>,	\
		<DCC_READ 0xF111654 1 0>,	\
		<DCC_READ 0xF111658 1 0>,	\
		<DCC_READ 0xF11165C 1 0>,	\
		<DCC_READ 0xF111660 1 0>,	\
		<DCC_READ 0xF111664 1 0>,	\
		<DCC_READ 0xF011400 1 0>,	\
		<DCC_READ 0xF111400 1 0>,	\
		<DCC_WRITE 0x9870010 0x0 0>

/* config_bengal_dcc_core() */
#define config_bengal_dcc_core	\
	\
		/*  core hang */	\
		<DCC_READ 0x0F1880B4 1 0>,	\
		<DCC_READ 0x0F1980B4 1 0>,	\
		<DCC_READ 0x0F1A80B4 1 0>,	\
		<DCC_READ 0x0F1B80B4 1 0>,	\
		<DCC_READ 0x0F0880B4 1 0>,	\
		<DCC_READ 0x0F0980B4 1 0>,	\
		<DCC_READ 0x0F0A80B4 1 0>,	\
		<DCC_READ 0x0F0B80B4 1 0>,	\
	\
		/* first core hung */	\
		<DCC_READ 0x0F1D1228 1 0>

/* config_bengal_dcc_cam() */
#define config_bengal_dcc_cam	\
		<DCC_READ 0x5C6F000 1 0>,	\
		<DCC_READ 0x5C42000 1 0>,	\
		<DCC_READ 0x5C42400 1 0>,	\
		<DCC_READ 0x5C23000 1 0>

/* dcc_async_package() */
#define dcc_async_package	\
	\
		/*  Function to send ASYNC package in TPDA */	\
		<DCC_WRITE 0x08004FB0 0xc5acce55 0>,	\
		<DCC_WRITE 0x0800408c 0xff 0>,	\
		<DCC_WRITE 0x08004FB0 0x0 0>

&dcc {
	dcc_curr_link@3 {
		qcom,curr-link-list = <3>;
		qcom,data-sink = "sram";
		qcom,link-list =
			config_bengal_dcc_core,
			config_bengal_dcc_qdsp,
			config_bengal_dcc_bimc,
			config_bengal_dcc_gpu,
			config_bengal_dcc_lpm,
			config_bengal_dcc_noc,
			config_bengal_dcc_misc,
			config_bengal_dcc_osm,
			config_acp_status,
			config_modem_rscc,
			config_cdsp_rscc,
			config_bengal_dcc_cam;
	};

	dcc_curr_link@2 {
		qcom,curr-link-list = <2>;
		qcom,data-sink = "atb";
		qcom,link-list =
			dcc_async_package,
			config_bengal_dcc_gcc_mm,
			config_bengal_dcc_gcc;
	};

};
